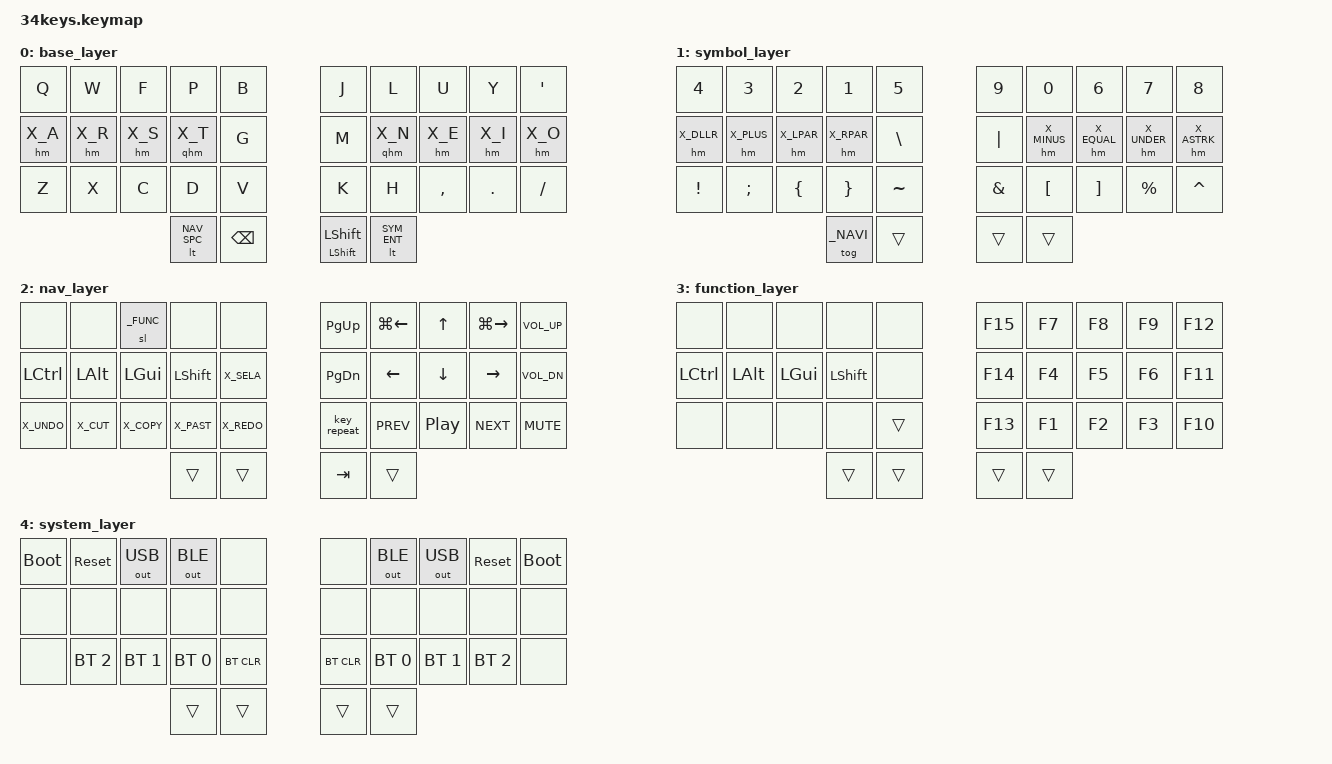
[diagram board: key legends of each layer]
/*
 * Copyright (c) 2021 The ZMK Contributors
 *
 * SPDX-License-Identifier: MIT
 */

#include <behaviors.dtsi>
#include <dt-bindings/zmk/keys.h>
#include <dt-bindings/zmk/bt.h>
#include <dt-bindings/zmk/outputs.h>
#include <dt-bindings/zmk/ext_power.h>
#include "halcyoncorsair.h"

&lt {
    tapping-term-ms = <250>;
    flavor = "tap-preferred";
};

&mt {
    tapping-term-ms = <200>;
};

&sk {
     release-after-ms = <1000>;
     quick-release;
};

&sl {
    /delete-property/ quick-release;
};

&caps_word {
    continue-list = <UNDERSCORE MINUS PIPE>; // BSPC
};

/ {
    behaviors {
        bhm: balanced_homerow_mods {
            compatible = "zmk,behavior-hold-tap";
            label = "HOMEROW_MODS";
            #binding-cells = <2>;
            tapping-term-ms = <200>;    // <---[[moderate duration]]
            quick-tap-ms = <0>;
            flavor = "balanced";
            bindings = <&kp>, <&kp>;
        };
        hm: homerow_mods {
            compatible = "zmk,behavior-hold-tap";
            label = "HOMEROW_MODS";
            #binding-cells = <2>;
            tapping-term-ms = <250>;
            quick-tap-ms = <0>;
            flavor = "tap-preferred";
            bindings = <&kp>, <&kp>;
        };
        qhm: quick_homerow_mods {
            compatible = "zmk,behavior-hold-tap";
            label = "QUICK_HOMEROW_MODS";
            #binding-cells = <2>;
            tapping-term-ms = <180>;
            quick-tap-ms = <0>;
            flavor = "tap-preferred";
            bindings = <&kp>, <&kp>;
        };
        ss: sticky_shift {
            compatible = "zmk,behavior-hold-tap";
            label = "STICKY_SHIFT";
            #binding-cells = <2>;
            tapping-term-ms = <150>;
            quick-tap-ms = <0>;
            flavor = "tap-preferred";
            bindings = <&kp>, <&sk>;
        };
    };

    combos {
        #include "combos.def"
    };

    keymap {
        compatible = "zmk,keymap";

        base_layer {
                        bindings = <
    &kp Q       &kp W       &kp F       &kp P       &kp B              &kp J       &kp L       &kp U       &kp Y       &kp SQT
    &hm X_A     &hm X_R     &hm X_S     &qhm X_T    &kp G              &kp M       &qhm X_N    &hm X_E     &hm X_I     &hm X_O
    &kp Z       &kp X       &kp C       &kp D       &kp V              &kp K       &kp H       &kp COMMA   &kp DOT     &kp FSLH
                                        &lt NAV_SPC &kp BSPC           &ss LSHIFT LSHIFT &lt SYM_ENT
                        >;
                };
        symbol_layer {
                        bindings = <
    &kp N4      &kp N3      &kp N2      &kp N1      &kp N5              &kp N9       &kp N0      &kp N6      &kp N7      &kp N8
    &hm X_DLLR  &hm X_PLUS  &hm X_LPAR  &hm X_RPAR  &kp BSLH            &kp PIPE     &hm X_MINUS &hm X_EQUAL &hm X_UNDER &hm X_ASTRK
    &kp EXCL    &kp SEMI    &kp LBRC    &kp RBRC    &kp TILDE           &kp AMPS     &kp LBKT    &kp RBKT    &kp PERCENT &kp CARET
                                        &tog _NAVI  &trans              &trans       &trans
                        >;
    // available due to combo: +, -, @, [, ]
    // need to find space for: \, ', "
                };
        nav_layer {
                        bindings = <
    &none       &none       &sl _FUNC   &none       &none              &kp PG_UP     &kp LG(LEFT) &kp UP      &kp LG(RIGHT) &kp C_VOL_UP
    &kp LCTRL   &kp LALT    &kp LGUI    &kp LSHFT   &kp X_SELA         &kp PG_DN     &kp LEFT     &kp DOWN    &kp RIGHT   &kp C_VOL_DN
    &kp X_UNDO  &kp X_CUT   &kp X_COPY  &kp X_PAST  &kp X_REDO         &key_repeat   &kp C_PREV   &kp C_PP    &kp C_NEXT  &kp C_MUTE
                                        &trans      &trans             &kp TAB       &trans
                        >;
                };
        function_layer {
                        bindings = <
    &none       &none       &none       &none       &none              &kp F15     &kp F7      &kp F8      &kp F9      &kp F12
    &kp LCTRL   &kp LALT    &kp LGUI    &kp LSHFT   &none              &kp F14     &kp F4      &kp F5      &kp F6      &kp F11
    &none       &none       &none       &none       &trans             &kp F13     &kp F1      &kp F2      &kp F3      &kp F10
                                        &trans      &trans             &trans      &trans
                        >;
                };
        system_layer {
                        bindings = <
    &bootloader     &sys_reset          &out OUT_USB    &out OUT_BLE    &none              &none        &out OUT_BLE    &out OUT_USB    &sys_reset          &bootloader
    &none           &none           &none           &none           &none              &none        &none           &none           &none           &none
    &none           &bt BT_SEL 2    &bt BT_SEL 1    &bt BT_SEL 0    &bt BT_CLR         &bt BT_CLR   &bt BT_SEL 0    &bt BT_SEL 1    &bt BT_SEL 2    &none
                                                    &trans          &trans             &trans       &trans
                        >;
                };
        };
};
